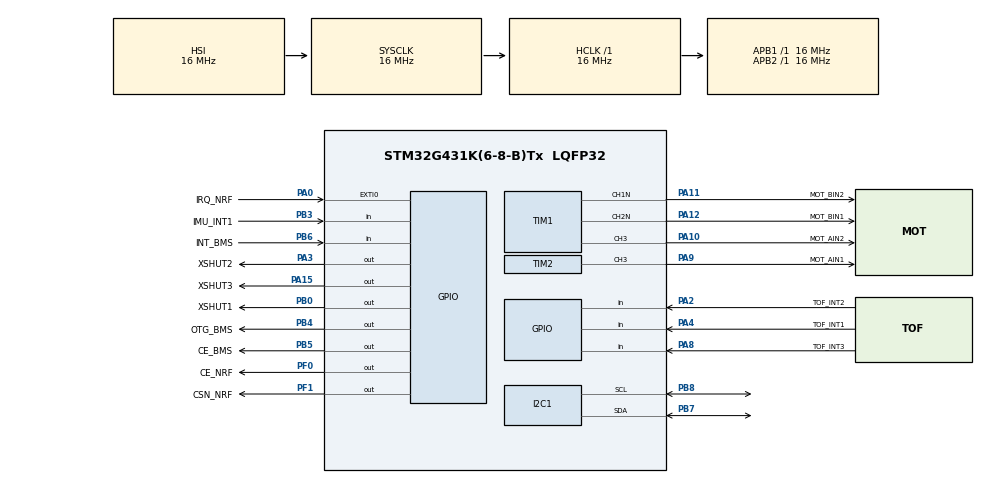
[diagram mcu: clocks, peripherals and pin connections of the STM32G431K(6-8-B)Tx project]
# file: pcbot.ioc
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I2C1.Timing=0x00503D58
Mcu.Family=STM32G4
Mcu.Name=STM32G431K(6-8-B)Tx
Mcu.Package=LQFP32
NVIC.PriorityGroup=NVIC_PRIORITYGROUP_4
PA0.GPIO_Label=IRQ_NRF
PA0.Signal=GPXTI0
PA10.GPIO_Label=MOT_AIN2
PA10.Signal=S_TIM1_CH3
PA11.GPIO_Label=MOT_BIN2
PA11.Mode=PWM Generation1 CH1N
PA11.Signal=TIM1_CH1N
PA12.GPIO_Label=MOT_BIN1
PA12.Mode=PWM Generation2 CH2N
PA12.Signal=TIM1_CH2N
PA13.Mode=Serial_Wire
PA13.Signal=SYS_JTMS-SWDIO
PA14.Mode=Serial_Wire
PA14.Signal=SYS_JTCK-SWCLK
PA15.GPIO_Label=XSHUT3
PA15.Signal=GPIO_Output
PA2.GPIO_Label=TOF_INT2
PA2.Signal=GPIO_Input
PA3.GPIO_Label=XSHUT2
PA3.Signal=GPIO_Output
PA4.GPIO_Label=TOF_INT1
PA4.Signal=GPIO_Input
PA5.Signal=SPI1_SCK
PA6.Signal=SPI1_MISO
PA7.Signal=SPI1_MOSI
PA8.GPIO_Label=TOF_INT3
PA8.Signal=GPIO_Input
PA9.GPIO_Label=MOT_AIN1
PA9.Signal=S_TIM2_CH3
PB0.GPIO_Label=XSHUT1
PB0.Signal=GPIO_Output
PB3.GPIO_Label=IMU_INT1
PB3.Signal=GPIO_Input
PB4.GPIO_Label=OTG_BMS
PB4.Signal=GPIO_Output
PB5.GPIO_Label=CE_BMS
PB5.Signal=GPIO_Output
PB6.GPIO_Label=INT_BMS
PB6.Signal=GPIO_Input
PB7.Mode=I2C
PB7.Signal=I2C1_SDA
PB8-BOOT0.Mode=I2C
PB8-BOOT0.Signal=I2C1_SCL
PF0-OSC_IN.GPIO_Label=CE_NRF
PF0-OSC_IN.Signal=GPIO_Output
PF1-OSC_OUT.GPIO_Label=CSN_NRF
PF1-OSC_OUT.Signal=GPIO_Output
ProjectManager.HeapSize=0x200
ProjectManager.StackSize=0x400
ProjectManager.TargetToolchain=CMake
RCC.AHBFreq_Value=16000000
RCC.APB1Freq_Value=16000000
RCC.APB1TimFreq_Value=16000000
RCC.APB2Freq_Value=16000000
RCC.APB2TimFreq_Value=16000000
RCC.CortexFreq_Value=16000000
RCC.EXTERNAL_CLOCK_VALUE=12288000
RCC.HCLKFreq_Value=16000000
RCC.HSE_VALUE=8000000
RCC.HSI48_VALUE=48000000
RCC.HSI_VALUE=16000000
RCC.LSE_VALUE=32768
RCC.SYSCLKFreq_VALUE=16000000
RCC.USBFreq_Value=64000000
RCC.VCOOutputFreq_Value=128000000
SH.S_TIM1_CH3.0=TIM1_CH3,PWM Generation3 CH3
SH.S_TIM2_CH3.0=TIM2_CH3,PWM Generation3 CH3
TIM1.Channel-PWM\ Generation1\ CH1N=TIM_CHANNEL_1
TIM1.Channel-PWM\ Generation2\ CH2N=TIM_CHANNEL_2
TIM1.Channel-PWM\ Generation3\ CH3=TIM_CHANNEL_3
TIM2.Channel-PWM\ Generation3\ CH3=TIM_CHANNEL_3
VP_SYS_VS_DBSignals.Mode=DisableDeadBatterySignals
VP_TIM1_VS_ClockSourceINT.Mode=Internal
board=custom

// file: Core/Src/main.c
/* USER CODE BEGIN Header */
/**
  ******************************************************************************
  * @file           : main.c
  * @brief          : Main program body
  ******************************************************************************
  * @attention
  *
  * Copyright (c) 2026 STMicroelectronics.
  * All rights reserved.
  *
  * This software is licensed under terms that can be found in the LICENSE file
  * in the root directory of this software component.
  * If no LICENSE file comes with this software, it is provided AS-IS.
  *
  ******************************************************************************
  */
/* USER CODE END Header */
#include "main.h"
#include "motors.h"
#include "robot.h"

I2C_HandleTypeDef hi2c1;

TIM_HandleTypeDef htim1;
TIM_HandleTypeDef htim2;

void SystemClock_Config(void);
static void MX_GPIO_Init(void);
static void MX_I2C1_Init(void);
static void MX_TIM1_Init(void);
static void MX_TIM2_Init(void);

int main(void)
{

  /* MCU Configuration--------------------------------------------------------*/

  /* Reset of all peripherals, Initializes the Flash interface and the Systick. */
  HAL_Init();

  /* Configure the system clock */
  SystemClock_Config();

  /* Initialize all configured peripherals */
  MX_GPIO_Init();
  MX_I2C1_Init();
  MX_TIM1_Init();
  MX_TIM2_Init();
  Motors_Init();
  /* USER CODE BEGIN 2 */
  RobotMode_t currentMode = MODE_NAVIGATION;
  // IMU_Calibration();

if (!initVL53L0X(true, &hi2c1)) {
    // Erreur d'initialisation (problème de câblage ou d'adresse I2C)
    return 0
}

  /* USER CODE END 2 */

  /* Infinite loop */
  /* USER CODE BEGIN WHILE */
  while (1)
  {
    Robot_logic(&currentMode);

    //uint32_t tickstart = HAL_GetTick();
    //IMU_getacceleration + calculer position
    //Transmettre les données sur nRF24
    Tof_Distance();
    float vL=0.0f , vR= 0.0f;
    Compute_asserv(dist_front, &vL, &vR);
    apply_motor_speeds(vL, vR);

    HAL_Delay (20);
    //while delay
    /* USER CODE END WHILE */

  }
}

void SystemClock_Config(void)
{
  RCC_OscInitTypeDef RCC_OscInitStruct = {0};
  RCC_ClkInitTypeDef RCC_ClkInitStruct = {0};

  /** Configure the main internal regulator output voltage
  */
  HAL_PWREx_ControlVoltageScaling(PWR_REGULATOR_VOLTAGE_SCALE1);

  /** Initializes the RCC Oscillators according to the specified parameters
  * in the RCC_OscInitTypeDef structure.
  */
  RCC_OscInitStruct.OscillatorType = RCC_OSCILLATORTYPE_HSI;
  RCC_OscInitStruct.HSIState = RCC_HSI_ON;
  RCC_OscInitStruct.HSICalibrationValue = RCC_HSICALIBRATION_DEFAULT;
  RCC_OscInitStruct.PLL.PLLState = RCC_PLL_NONE;
  if (HAL_RCC_OscConfig(&RCC_OscInitStruct) != HAL_OK)
  {
    Error_Handler();
  }

  /** Initializes the CPU, AHB and APB buses clocks
  */
  RCC_ClkInitStruct.ClockType = RCC_CLOCKTYPE_HCLK|RCC_CLOCKTYPE_SYSCLK
                              |RCC_CLOCKTYPE_PCLK1|RCC_CLOCKTYPE_PCLK2;
  RCC_ClkInitStruct.SYSCLKSource = RCC_SYSCLKSOURCE_HSI;
  RCC_ClkInitStruct.AHBCLKDivider = RCC_SYSCLK_DIV1;
  RCC_ClkInitStruct.APB1CLKDivider = RCC_HCLK_DIV1;
  RCC_ClkInitStruct.APB2CLKDivider = RCC_HCLK_DIV1;

  if (HAL_RCC_ClockConfig(&RCC_ClkInitStruct, FLASH_LATENCY_0) != HAL_OK)
  {
    Error_Handler();
  }
}

static void MX_I2C1_Init(void)
{

  hi2c1.Instance = I2C1;
  hi2c1.Init.Timing = 0x00503D58;
  hi2c1.Init.OwnAddress1 = 0;
  hi2c1.Init.AddressingMode = I2C_ADDRESSINGMODE_7BIT;
  hi2c1.Init.DualAddressMode = I2C_DUALADDRESS_DISABLE;
  hi2c1.Init.OwnAddress2 = 0;
  hi2c1.Init.OwnAddress2Masks = I2C_OA2_NOMASK;
  hi2c1.Init.GeneralCallMode = I2C_GENERALCALL_DISABLE;
  hi2c1.Init.NoStretchMode = I2C_NOSTRETCH_DISABLE;
  if (HAL_I2C_Init(&hi2c1) != HAL_OK)
  {
    Error_Handler();
  }

  /** Configure Analogue filter
  */
  if (HAL_I2CEx_ConfigAnalogFilter(&hi2c1, I2C_ANALOGFILTER_ENABLE) != HAL_OK)
  {
    Error_Handler();
  }

  /** Configure Digital filter
  */
  if (HAL_I2CEx_ConfigDigitalFilter(&hi2c1, 0) != HAL_OK)
  {
    Error_Handler();
  }

}

static void MX_TIM1_Init(void)
{

  TIM_ClockConfigTypeDef sClockSourceConfig = {0};
  TIM_MasterConfigTypeDef sMasterConfig = {0};
  TIM_OC_InitTypeDef sConfigOC = {0};
  TIM_BreakDeadTimeConfigTypeDef sBreakDeadTimeConfig = {0};

  htim1.Instance = TIM1;
  htim1.Init.Prescaler = 0;
  htim1.Init.CounterMode = TIM_COUNTERMODE_UP;
  htim1.Init.Period = 65535;
  htim1.Init.ClockDivision = TIM_CLOCKDIVISION_DIV1;
  htim1.Init.RepetitionCounter = 0;
  htim1.Init.AutoReloadPreload = TIM_AUTORELOAD_PRELOAD_DISABLE;
  if (HAL_TIM_Base_Init(&htim1) != HAL_OK)
  {
    Error_Handler();
  }
  sClockSourceConfig.ClockSource = TIM_CLOCKSOURCE_INTERNAL;
  if (HAL_TIM_ConfigClockSource(&htim1, &sClockSourceConfig) != HAL_OK)
  {
    Error_Handler();
  }
  if (HAL_TIM_PWM_Init(&htim1) != HAL_OK)
  {
    Error_Handler();
  }
  sMasterConfig.MasterOutputTrigger = TIM_TRGO_RESET;
  sMasterConfig.MasterOutputTrigger2 = TIM_TRGO2_RESET;
  sMasterConfig.MasterSlaveMode = TIM_MASTERSLAVEMODE_DISABLE;
  if (HAL_TIMEx_MasterConfigSynchronization(&htim1, &sMasterConfig) != HAL_OK)
  {
    Error_Handler();
  }
  sConfigOC.OCMode = TIM_OCMODE_PWM1;
  sConfigOC.Pulse = 0;
  sConfigOC.OCPolarity = TIM_OCPOLARITY_HIGH;
  sConfigOC.OCNPolarity = TIM_OCNPOLARITY_HIGH;
  sConfigOC.OCFastMode = TIM_OCFAST_DISABLE;
  sConfigOC.OCIdleState = TIM_OCIDLESTATE_RESET;
  sConfigOC.OCNIdleState = TIM_OCNIDLESTATE_RESET;
  if (HAL_TIM_PWM_ConfigChannel(&htim1, &sConfigOC, TIM_CHANNEL_1) != HAL_OK)
  {
    Error_Handler();
  }
  if (HAL_TIM_PWM_ConfigChannel(&htim1, &sConfigOC, TIM_CHANNEL_2) != HAL_OK)
  {
    Error_Handler();
  }
  if (HAL_TIM_PWM_ConfigChannel(&htim1, &sConfigOC, TIM_CHANNEL_3) != HAL_OK)
  {
    Error_Handler();
  }
  sBreakDeadTimeConfig.OffStateRunMode = TIM_OSSR_DISABLE;
  sBreakDeadTimeConfig.OffStateIDLEMode = TIM_OSSI_DISABLE;
  sBreakDeadTimeConfig.LockLevel = TIM_LOCKLEVEL_OFF;
  sBreakDeadTimeConfig.DeadTime = 0;
  sBreakDeadTimeConfig.BreakState = TIM_BREAK_DISABLE;
  sBreakDeadTimeConfig.BreakPolarity = TIM_BREAKPOLARITY_HIGH;
  sBreakDeadTimeConfig.BreakFilter = 0;
  sBreakDeadTimeConfig.BreakAFMode = TIM_BREAK_AFMODE_INPUT;
  sBreakDeadTimeConfig.Break2State = TIM_BREAK2_DISABLE;
  sBreakDeadTimeConfig.Break2Polarity = TIM_BREAK2POLARITY_HIGH;
  sBreakDeadTimeConfig.Break2Filter = 0;
  sBreakDeadTimeConfig.Break2AFMode = TIM_BREAK_AFMODE_INPUT;
  sBreakDeadTimeConfig.AutomaticOutput = TIM_AUTOMATICOUTPUT_DISABLE;
  if (HAL_TIMEx_ConfigBreakDeadTime(&htim1, &sBreakDeadTimeConfig) != HAL_OK)
  {
    Error_Handler();
  }
  HAL_TIM_MspPostInit(&htim1);

}

static void MX_TIM2_Init(void)
{

  TIM_MasterConfigTypeDef sMasterConfig = {0};
  TIM_OC_InitTypeDef sConfigOC = {0};

  htim2.Instance = TIM2;
  htim2.Init.Prescaler = 0;
  htim2.Init.CounterMode = TIM_COUNTERMODE_UP;
  htim2.Init.Period = 4294967295;
  htim2.Init.ClockDivision = TIM_CLOCKDIVISION_DIV1;
  htim2.Init.AutoReloadPreload = TIM_AUTORELOAD_PRELOAD_DISABLE;
  if (HAL_TIM_PWM_Init(&htim2) != HAL_OK)
  {
    Error_Handler();
  }
  sMasterConfig.MasterOutputTrigger = TIM_TRGO_RESET;
  sMasterConfig.MasterSlaveMode = TIM_MASTERSLAVEMODE_DISABLE;
  if (HAL_TIMEx_MasterConfigSynchronization(&htim2, &sMasterConfig) != HAL_OK)
  {
    Error_Handler();
  }
  sConfigOC.OCMode = TIM_OCMODE_PWM1;
  sConfigOC.Pulse = 0;
  sConfigOC.OCPolarity = TIM_OCPOLARITY_HIGH;
  sConfigOC.OCFastMode = TIM_OCFAST_DISABLE;
  if (HAL_TIM_PWM_ConfigChannel(&htim2, &sConfigOC, TIM_CHANNEL_3) != HAL_OK)
  {
    Error_Handler();
  }
  HAL_TIM_MspPostInit(&htim2);

}

static void MX_GPIO_Init(void)
{
  GPIO_InitTypeDef GPIO_InitStruct = {0};

  /* GPIO Ports Clock Enable */
  __HAL_RCC_GPIOF_CLK_ENABLE();
  __HAL_RCC_GPIOA_CLK_ENABLE();
  __HAL_RCC_GPIOB_CLK_ENABLE();

  /*Configure GPIO pin Output Level */
  HAL_GPIO_WritePin(GPIOF, CE_NRF_Pin|CSN_NRF_Pin, GPIO_PIN_RESET);

  /*Configure GPIO pin Output Level */
  HAL_GPIO_WritePin(GPIOA, XSHUT2_Pin|XSHUT3_Pin, GPIO_PIN_RESET);

  /*Configure GPIO pin Output Level */
  HAL_GPIO_WritePin(GPIOB, XSHUT1_Pin|IMU_INT1_Pin|OTG_BMS_Pin|CE_BMS_Pin, GPIO_PIN_RESET);

  /*Configure GPIO pins : CE_NRF_Pin CSN_NRF_Pin */
  GPIO_InitStruct.Pin = CE_NRF_Pin|CSN_NRF_Pin;
  GPIO_InitStruct.Mode = GPIO_MODE_OUTPUT_PP;
  GPIO_InitStruct.Pull = GPIO_NOPULL;
  GPIO_InitStruct.Speed = GPIO_SPEED_FREQ_LOW;
  HAL_GPIO_Init(GPIOF, &GPIO_InitStruct);

  /*Configure GPIO pin : IRQ_NRF_Pin */
  GPIO_InitStruct.Pin = IRQ_NRF_Pin;
  GPIO_InitStruct.Mode = GPIO_MODE_IT_RISING;
  GPIO_InitStruct.Pull = GPIO_NOPULL;
  HAL_GPIO_Init(IRQ_NRF_GPIO_Port, &GPIO_InitStruct);

  /*Configure GPIO pins : TOF_INT2_Pin TOF_INT1_Pin TOF_INT3_Pin */
  GPIO_InitStruct.Pin = TOF_INT2_Pin|TOF_INT1_Pin|TOF_INT3_Pin;
  GPIO_InitStruct.Mode = GPIO_MODE_INPUT;
  GPIO_InitStruct.Pull = GPIO_NOPULL;
  HAL_GPIO_Init(GPIOA, &GPIO_InitStruct);

  /*Configure GPIO pins : XSHUT2_Pin XSHUT3_Pin */
  GPIO_InitStruct.Pin = XSHUT2_Pin|XSHUT3_Pin;
  GPIO_InitStruct.Mode = GPIO_MODE_OUTPUT_PP;
  GPIO_InitStruct.Pull = GPIO_NOPULL;
  GPIO_InitStruct.Speed = GPIO_SPEED_FREQ_LOW;
  HAL_GPIO_Init(GPIOA, &GPIO_InitStruct);

  /*Configure GPIO pins : PA5 PA6 PA7 */
  GPIO_InitStruct.Pin = GPIO_PIN_5|GPIO_PIN_6|GPIO_PIN_7;
  GPIO_InitStruct.Mode = GPIO_MODE_AF_PP;
  GPIO_InitStruct.Pull = GPIO_NOPULL;
  GPIO_InitStruct.Speed = GPIO_SPEED_FREQ_LOW;
  GPIO_InitStruct.Alternate = GPIO_AF5_SPI1;
  HAL_GPIO_Init(GPIOA, &GPIO_InitStruct);

  /*Configure GPIO pins : XSHUT1_Pin IMU_INT1_Pin OTG_BMS_Pin CE_BMS_Pin */
  GPIO_InitStruct.Pin = XSHUT1_Pin|IMU_INT1_Pin|OTG_BMS_Pin|CE_BMS_Pin;
  GPIO_InitStruct.Mode = GPIO_MODE_OUTPUT_PP;
  GPIO_InitStruct.Pull = GPIO_NOPULL;
  GPIO_InitStruct.Speed = GPIO_SPEED_FREQ_LOW;
  HAL_GPIO_Init(GPIOB, &GPIO_InitStruct);

  /*Configure GPIO pin : INT_BMS_Pin */
  GPIO_InitStruct.Pin = INT_BMS_Pin;
  GPIO_InitStruct.Mode = GPIO_MODE_INPUT;
  GPIO_InitStruct.Pull = GPIO_NOPULL;
  HAL_GPIO_Init(INT_BMS_GPIO_Port, &GPIO_InitStruct);

}

void Error_Handler(void)
{
  __disable_irq();
  while (1)
  {
  }
}
